# CONTROLSS_EQEP1_CONTROLSS_EQEP1 register map
Vendor: Texas Instruments
Peripheral module from a debugger description file (folder AM263).
Registers are 16-bit, read-write, reset 0x0 unless marked. A register's access mark holds for its fields unless they carry their own. Offsets are as the file gives them; lines under a group give offsets from that group; [hi:lo] are bit positions; {n}, {i} and the like mark numbered series; 'fields as' and 'values as' point back to an identical list; <NAME> marks a mode.

## CONTROLSS_EQEP1_CONTROLSS_EQEP1
0x00 CONTROLSS_EQEP1_QPOSCNT 32-bit
  [31:0] QPOSCNT — Position Counter This 32-bit position counter register counts up/down on every eQEP pulse based on direction input. This counter acts as a position integrator whose count value is proportional to position from a give reference point. This Register acts as a Read ONLY register while counter is counting up/down. Note: It is recommended to only write to the position counter register (QPOSCNT) during initialization, i.e. when the eQEP position counter is disabled (QPEN bit of QEPCTL is zero). Once the position counter is enabled (QPEN bit is one), writing to the eQEP position counter register (QPOSCNT) may cause unexpected results.
0x04 CONTROLSS_EQEP1_QPOSINIT 32-bit
  [31:0] QPOSINIT — Position Counter Init This register contains the position value that is used to initialize the position counter based on external strobe or index event. The position counter can be initialized through software. Writes to this register should always be full 32-bit writes.
0x08 CONTROLSS_EQEP1_QPOSMAX 32-bit
  [31:0] QPOSMAX — Maximum Position Count This register contains the maximum position counter value. Writes to this register should always be full 32-bit writes.
0x0C CONTROLSS_EQEP1_QPOSCMP 32-bit
  [31:0] QPOSCMP — Position Compare The position-compare value in this register is compared with the position counter (QPOSCNT) to generate sync output and/or interrupt on compare match.
0x10 CONTROLSS_EQEP1_QPOSILAT 32-bit ro
  [31:0] QPOSILAT — Index Position Latch The position-counter value is latched into this register on an index event as defined by the QEPCTL[IEL] bits.
0x14 CONTROLSS_EQEP1_QPOSSLAT 32-bit ro
  [31:0] QPOSSLAT — Strobe Position Latch The position-counter value is latched into this register on a strobe event as defined by the QEPCTL[SEL] bits.
0x18 CONTROLSS_EQEP1_QPOSLAT 32-bit ro
  [31:0] QPOSLAT — Position Latch The position-counter value is latched into this register on a unit time out event.
0x1C CONTROLSS_EQEP1_QUTMR 32-bit
  [31:0] QUTMR — QEP Unit Timer This register acts as time base for unit time event generation. When this timer value matches the unit time period value a unit time event is generated.
0x20 CONTROLSS_EQEP1_QUPRD 32-bit
  [31:0] QUPRD — QEP Unit Period This register contains the period count for the unit timer to generate periodic unit time events. These events latch the eQEP position information at periodic intervals and optionally generate an interrupt. Writes to this register should always be full 32-bit writes.
0x24 CONTROLSS_EQEP1_QWDTMR
  [15:0] QWDTMR — QEP Watchdog Timer This register acts as time base for the watchdog to detect motor stalls. When this timer value matches with the watchdog's period value a watchdog timeout interrupt is generated. This register is reset upon edge transition in quadrature-clock indicating the motion.
0x26 CONTROLSS_EQEP1_QWDPRD
  [15:0] QWDPRD — QEP Watchdog Period This register contains the time-out count for the eQEP peripheral watch dog timer. When the watchdog timer value matches the watchdog period value, a watchdog timeout interrupt is generated.
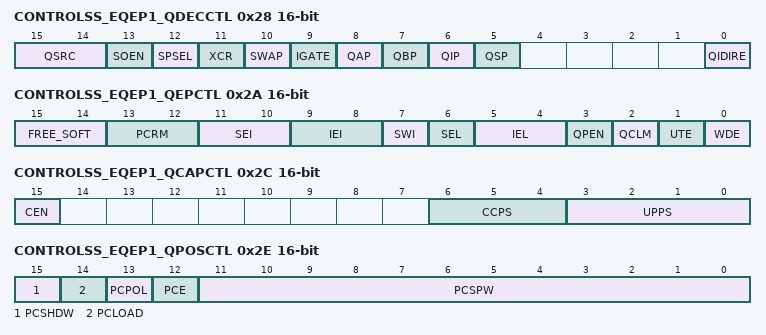
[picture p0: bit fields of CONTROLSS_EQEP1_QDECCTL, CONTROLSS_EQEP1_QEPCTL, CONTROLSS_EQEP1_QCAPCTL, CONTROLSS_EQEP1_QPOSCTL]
0x28 CONTROLSS_EQEP1_QDECCTL
  [15:14] QSRC — Position-counter source selection
  [13] SOEN — Sync output-enable 0 | SYNC_DISABLEDisable position-compare sync output 1 | SYNC_ENABLEEnable position-compare sync output
  [12] SPSEL — Sync output pin selection 0 | INDEX_PINIndex pin is used for sync output 1 | STROBE_PINStrobe pin is used for sync output
  [11] XCR — External Clock Rate 0 | XCR_2XRESOL2x resolution: Count the rising/falling edge 1 | XCR_1XRESOL1x resolution: Count the rising edge only
  [10] SWAP — CLK/DIR Signal Source for Position Counter 0 | SWAP_DISABLEQuadrature-clock inputs are not swapped 1 | SWAP_ENABLEQuadrature-clock inputs are swapped
  [9] IGATE — Index pulse gating option 0 | IGATE_DISABLEDisable gating of Index pulse 1 | IGATE_ENABLEGate the index pin with strobe
  [8] QAP — QEPA input polarity 0 | QAP_NOPOLARNo effect 1 | QAP_POLARNegates QEPA input
  [7] QBP — QEPB input polarity 0 | QBP_NOPOLARNo effect 1 | QBP_POLARNegates QEPB input
  [6] QIP — QEPI input polarity 0 | QIP_NOPOLARNo effect 1 | QIP_POLARNegates QEPI input
  [5] QSP — QEPS input polarity 0 | QSP_NOPOLARNo effect 1 | QSP_POLARNegates QEPS input
  [0] QIDIRE — 0 - Compatible mode, Behavior same as existing devices 1 - Enhancement for Direction change during Index will be enabled
0x2A CONTROLSS_EQEP1_QEPCTL
  [15:14] FREE_SOFT — Emulation mode 0x0 | FREE_SOFT_0QPOSCNT behavior Position counter stops immediately on emulation suspend 0h (R/W) = QWDTMR behavior Watchdog counter stops immediately 0h (R/W) = QUTMR behavior Unit timer stops immediately 0h (R/W) = QCTMR behavior Capture Timer stops immediately 0x1 | FREE_SOFT_1QPOSCNT behavior Position counter continues to count until the rollover 1h (R/W) = QWDTMR behavior Watchdog counter counts until WD period match roll over 1h (R/W) = QUTMR behavior Unit timer counts until period rollover 1h (R/W) = QCTMR behavior Capture Timer counts until next unit period event 0x2 | FREE_SOFT_2QPOSCNT behavior Position counter is unaffected by emulation suspend 2h (R/W) = QWDTMR behavior Watchdog counter is unaffected by emulation suspend 2h (R/W) = QUTMR behavior Unit timer is unaffected by emulation suspend 2h (R/W) = QCTMR behavior Capture Timer is unaffected by emulation suspend 0x3 | FREE_SOFT_3Same as FREE_SOFT_2
  [13:12] PCRM — Postion counter reset 0x0 | PCRM_INDEXPosition counter reset on an index event 0x1 | PCRM_MAXPOSPosition counter reset on the maximum position 0x2 | PCRM_FIRSTINDEXPosition counter reset on the first index event 0x3 | PCRM_TIMEEVENTPosition counter reset on a unit time event
  [11:10] SEI — Strobe event initialization of position counter 0x0 | SEI_NOTHING0Does nothing (action disabled) 0x1 | SEI_NOTHING1Does nothing (action disabled) 0x2 | SEI_INITQEPSRISINGInitializes the position counter on rising edge of the QEPS signal 0x3 | SEI_INITQEPSCLOCKClockwise Direction: Initializes the position counter on the rising edge of QEPS strobe Counter Clockwise Direction: Initializes the position counter on the falling edge of QEPS strobe
  [9:8] IEI — Index event init of position count 0x0 | IEI_NOTHING0Do nothing (action disabled) 0x1 | IEI_NOTHING1Do nothing (action disabled) 0x2 | IEI_INITRISINGInitializes the position counter on the rising edge of the QEPI signal (QPOSCNT = QPOSINIT) 0x3 | IEI_INITFALLINGInitializes the position counter on the falling edge of QEPI signal (QPOSCNT = QPOSINIT)
  [7] SWI — Software init position counter 0 | SWI_NOTHINGDo nothing (action disabled) 1 | SWI_INITPOSInitialize position counter (QPOSCNT=QPOSINIT). This bit is not cleared automatically
  [6] SEL — Strobe event latch of position counter 0 | SEL_QEPSRISINGThe position counter is latched on the rising edge of QEPS strobe (QPOSSLAT = POSCCNT). Latching on the falling edge can be done by inverting the strobe input using the QSP bit in the QDECCTL register 1 | SEL_QEPSCLOCKClockwise Direction: Position counter is latched on rising edge of QEPS strobe Counter Clockwise Direction: Position counter is latched on falling edge of QEPS strobe
  [5:4] IEL — Index event latch of position counter (software index marker) 0x0 | IEL_RSVDReserved 0x1 | IEL_POSRISINGLatches position counter on rising edge of the index signal 0x2 | IEL_POSFALLINGLatches position counter on falling edge of the index signal 0x3 | IEL_SIMSoftware index marker. Latches the position counter and quadrature direction flag on index event marker. The position counter is latched to the QPOSILAT register and the direction flag is latched in the QEPSTS[QDLF] bit. This mode is useful for software index marking.
  [3] QPEN — Quadrature position counter enable/software reset 0 | QPEN_RESETReset the eQEP peripheral internal operating flags/read-only registers. Control/configuration registers are not disturbed by a software reset. When QPEN is disabled, some flags in the QFLG register do not get reset or cleared and show the actual state of that flag. 1 | QPEN_ENABLEeQEP position counter is enabled
  [2] QCLM — QEP capture latch mode 0 | QCLM_CPULatch on position counter read by CPU. Capture timer and capture period values are latched into QCTMRLAT and QCPRDLAT registers when CPU reads the QPOSCNT register. 1 | QCLM_TIMEOUTLatch on unit time out. Position counter, capture timer and capture period values are latched into QPOSLAT, QCTMRLAT and QCPRDLAT registers on unit time out.
  [1] UTE — QEP unit timer enable 0 | UTE_DISABLEDisable eQEP unit timer 1 | UTE_ENABLEEnable unit timer
  [0] WDE — QEP watchdog enable 0 | WDE_DISABLEDisable the eQEP watchdog timer 1 | WDE_ENABLEEnable the eQEP watchdog timer
0x2C CONTROLSS_EQEP1_QCAPCTL
  [15] CEN — Enable eQEP capture 0 | CEN_DISABLEeQEP capture unit is disabled 1 | CEN_ENABLEeQEP capture unit is enabled
  [6:4] CCPS — eQEP capture timer clock prescaler 0x0 | SYSCLKOUT1CAPCLK = SYSCLKOUT/1 0x1 | SYSCLKOUT2CAPCLK = SYSCLKOUT/2 0x2 | SYSCLKOUT4CAPCLK = SYSCLKOUT/4 0x3 | SYSCLKOUT8CAPCLK = SYSCLKOUT/8 0x4 | SYSCLKOUT16CAPCLK = SYSCLKOUT/16 0x5 | SYSCLKOUT32CAPCLK = SYSCLKOUT/32 0x6 | SYSCLKOUT64CAPCLK = SYSCLKOUT/64 0x7 | SYSCLKOUT128CAPCLK = SYSCLKOUT/128
  [3:0] UPPS — Unit position event prescaler 0x0 | QCLK1UPEVNT = QCLK/1 0x1 | QCLK2UPEVNT = QCLK/2 0x2 | QCLK4UPEVNT = QCLK/4 0x3 | QCLK8UPEVNT = QCLK/8 0x4 | QCLK16UPEVNT = QCLK/16 0x5 | QCLK32UPEVNT = QCLK/32 0x6 | QCLK64UPEVNT = QCLK/64 0x7 | QCLK128UPEVNT = QCLK/128 0x8 | QCLK256UPEVNT = QCLK/256 0x9 | QCLK512UPEVNT = QCLK/512 0xA | QCLK1024UPEVNT = QCLK/1024 0xB | QCLK2048UPEVNT = QCLK/2048 0xC | QCLK_RSVD0Reserved 0xD | QCLK_RSVD1Reserved 0xE | QCLK_RSVD2Reserved 0xF | QCLK_RSVD3Reserved
0x2E CONTROLSS_EQEP1_QPOSCTL
  [15] PCSHDW — Position compare of shadow enable 0 | PCSHDW_DISABLEShadow disabled, load Immediate 1 | PCSHDW_ENABLEShadow enabled
  [14] PCLOAD — Position compare of shadow load 0 | PCLOAD_0Load on QPOSCNT = 0 1 | PCLOAD_QPOSCMPLoad when QPOSCNT = QPOSCMP
  [13] PCPOL — Polarity of sync output 0 | PCPOL_HIGHActive HIGH pulse output 1 | PCPOL_LOWActive LOW pulse output
  [12] PCE — Position compare enable/disable 0 | PCE_DISABLEDisable position compare unit 1 | PCE_ENABLEEnable position compare unit
  [11:0] PCSPW — Select-position-compare sync output pulse width 0x000 | SYSCLKOUT41 * 4 * SYSCLKOUT cycles 0x001 | SYSCLKOUT82 * 4 * SYSCLKOUT cycles 0xFFF | SYSCLKOUT163844096 * 4 * SYSCLKOUT cycles
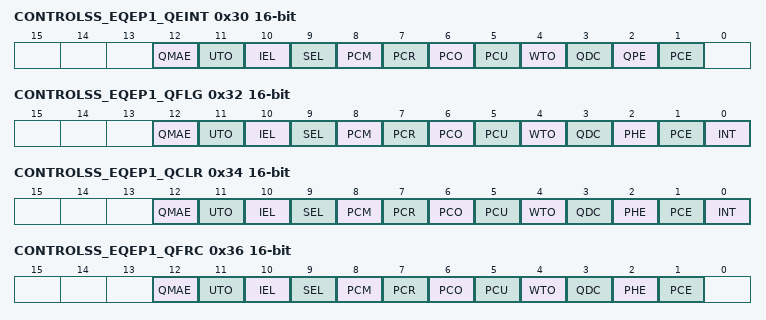
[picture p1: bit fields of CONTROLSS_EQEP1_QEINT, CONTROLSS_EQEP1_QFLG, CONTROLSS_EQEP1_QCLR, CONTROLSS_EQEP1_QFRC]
0x30 CONTROLSS_EQEP1_QEINT
  [12] QMAE — QMA Error Interrupt enable 0 | QMAE_DISABLEInterrupt is disabled 1 | QMAE_ENABLEInterrupt is enabled
  [11] UTO — Unit time out interrupt enable 0 | UTO_DISABLEInterrupt is disabled 1 | UTO_ENABLEInterrupt is enabled
  [10] IEL — Index event latch interrupt enable 0 | IEL_DISABLEInterrupt is disabled 1 | IEL_ENABLEInterrupt is enabled
  [9] SEL — Strobe event latch interrupt enable 0 | SEL_DISABLEInterrupt is disabled 1 | SEL_ENABLEInterrupt is enabled
  [8] PCM — Position-compare match interrupt enable 0 | PCM_DISABLEInterrupt is disabled 1 | PCM_ENABLEInterrupt is enabled
  [7] PCR — Position-compare ready interrupt enable 0 | PCR_DISABLEInterrupt is disabled 1 | PCR_ENABLEInterrupt is enabled
  [6] PCO — Position counter overflow interrupt enable 0 | PCO_DISABLEInterrupt is disabled 1 | PCO_ENABLEInterrupt is enabled
  [5] PCU — Position counter underflow interrupt enable 0 | PCU_DISABLEInterrupt is disabled 1 | PCU_ENABLEInterrupt is enabled
  [4] WTO — Watchdog time out interrupt enable 0 | WTO_DISABLEInterrupt is disabled 1 | WTO_ENABLEInterrupt is enabled
  [3] QDC — Quadrature direction change interrupt enable 0 | QDC_DISABLEInterrupt is disabled 1 | QDC_ENABLEInterrupt is enabled
  [2] QPE — Quadrature phase error interrupt enable 0 | QPE_DISABLEInterrupt is disabled 1 | QPE_ENABLEInterrupt is enabled
  [1] PCE — Position counter error interrupt enable 0 | PCE_DISABLEInterrupt is disabled 1 | PCE_ENABLEInterrupt is enabled
0x32 CONTROLSS_EQEP1_QFLG ro
  [12] QMAE — QMA Error interrupt flag Read0 | QMAE_NOFLAGNo interrupt generated Read1 | QMAE_FLAGInterrupt was generated
  [11] UTO — Unit time out interrupt flag Read0 | UTO_NOFLAGNo interrupt generated Read1 | UTO_FLAGSet by eQEP unit timer period match
  [10] IEL — Index event latch interrupt flag Read0 | IEL_NOFLAGNo interrupt generated Read1 | IEL_FLAGThis bit is set after latching the QPOSCNT to QPOSILAT
  [9] SEL — Strobe event latch interrupt flag Read0 | SEL_NOFLAGNo interrupt generated Read1 | SEL_FLAGThis bit is set after latching the QPOSCNT to QPOSSLAT
  [8] PCM — eQEP compare match event interrupt flag Read0 | PCM_NOFLAGNo interrupt generated Read1 | PCM_FLAGThis bit is set on position-compare match
  [7] PCR — Position-compare ready interrupt flag Read0 | PCR_NOFLAGNo interrupt generated Read1 | PCR_FLAGThis bit is set after transferring the shadow register value to the active position compare register
  [6] PCO — Position counter overflow interrupt flag Read0 | PCO_NOFLAGNo interrupt generated Read1 | PCO_FLAGThis bit is set on position counter overflow.
  [5] PCU — Position counter underflow interrupt flag Read0 | PCU_NOFLAGNo interrupt generated Read1 | PCU_FLAGThis bit is set on position counter underflow.
  [4] WTO — Watchdog timeout interrupt flag Read0 | WTO_NOFLAGNo interrupt generated Read1 | WTO_FLAGSet by watchdog timeout
  [3] QDC — Quadrature direction change interrupt flag Read0 | QDC_NOFLAGNo interrupt generated Read1 | QDC_FLAGInterrupt was generated
  [2] PHE — Quadrature phase error interrupt flag Read0 | PHE_NOFLAGNo interrupt generated Read1 | PHE_FLAGSet on simultaneous transition of QEPA and QEPB
  [1] PCE — Position counter error interrupt flag Read0 | PCE_NOFLAGNo interrupt generated Read1 | PCE_FLAGPosition counter error
  [0] INT — Global interrupt status flag Read0 | INT_NOFLAGNo interrupt generated Read1 | INT_FLAGInterrupt was generated
0x34 CONTROLSS_EQEP1_QCLR access not given
  [12] QMAE — Clear QMA Error interrupt flag 0 | QMAE_NOEFFECTNo effect 1 | QMAE_CLRClears the interrupt flag (access RW RRETURNS0S)
  [11] UTO — Clear unit time out interrupt flag 0 | UTO_NOEFFECTNo effect 1 | UTO_CLRClears the interrupt flag (access RW RRETURNS0S)
  [10] IEL — Clear index event latch interrupt flag 0 | IEL_NOEFFECTNo effect 1 | IEL_CLRClears the interrupt flag (access RW RRETURNS0S)
  [9] SEL — Clear strobe event latch interrupt flag 0 | SEL_NOEFFECTNo effect 1 | SEL_CLRClears the interrupt flag (access RW RRETURNS0S)
  [8] PCM — Clear eQEP compare match event interrupt flag 0 | PCM_NOEFFECTNo effect 1 | PCM_CLRClears the interrupt flag (access RW RRETURNS0S)
  [7] PCR — Clear position-compare ready interrupt flag 0 | PCR_NOEFFECTNo effect 1 | PCR_CLRClears the interrupt flag (access RW RRETURNS0S)
  [6] PCO — Clear position counter overflow interrupt flag 0 | PCO_NOEFFECTNo effect 1 | PCO_CLRClears the interrupt flag (access RW RRETURNS0S)
  [5] PCU — Clear position counter underflow interrupt flag 0 | PCU_NOEFFECTNo effect 1 | PCU_CLRClears the interrupt flag (access RW RRETURNS0S)
  [4] WTO — Clear watchdog timeout interrupt flag 0 | WTO_NOEFFECTNo effect 1 | WTO_CLRClears the interrupt flag (access RW RRETURNS0S)
  [3] QDC — Clear quadrature direction change interrupt flag 0 | QDC_NOEFFECTNo effect 1 | QDC_CLRClears the interrupt flag (access RW RRETURNS0S)
  [2] PHE — Clear quadrature phase error interrupt flag 0 | PHE_NOEFFECTNo effect 1 | PHE_CLRClears the interrupt flag (access RW RRETURNS0S)
  [1] PCE — Clear position counter error interrupt flag 0 | PCE_NOEFFECTNo effect 1 | PCE_CLRClears the interrupt flag (access RW RRETURNS0S)
  [0] INT — Global interrupt clear flag 0 | INT_NOEFFECTNo effect 1 | INT_CLRClears the interrupt flag (access RW RRETURNS0S)
0x36 CONTROLSS_EQEP1_QFRC
  [12] QMAE — Force QMA error interrupt 0 | QMAE_NOEFFECTNo effect 1 | QMAE_FORCEForce the interrupt
  [11] UTO — Force unit time out interrupt 0 | UTO_NOEFFECTNo effect 1 | UTO_FORCEForce the interrupt
  [10] IEL — Force index event latch interrupt 0 | IEL_NOEFFECTNo effect 1 | IEL_FORCEForce the interrupt
  [9] SEL — Force strobe event latch interrupt 0 | SEL_NOEFFECTNo effect 1 | SEL_FORCEForce the interrupt
  [8] PCM — Force position-compare match interrupt 0 | PCM_NOEFFECTNo effect 1 | PCM_FORCEForce the interrupt
  [7] PCR — Force position-compare ready interrupt 0 | PCR_NOEFFECTNo effect 1 | PCR_FORCEForce the interrupt
  [6] PCO — Force position counter overflow interrupt 0 | PCO_NOEFFECTNo effect 1 | PCO_FORCEForce the interrupt
  [5] PCU — Force position counter underflow interrupt 0 | PCU_NOEFFECTNo effect 1 | PCU_FORCEForce the interrupt
  [4] WTO — Force watchdog time out interrupt 0 | WTO_NOEFFECTNo effect 1 | WTO_FORCEForce the interrupt
  [3] QDC — Force quadrature direction change interrupt 0 | QDC_NOEFFECTNo effect 1 | QDC_FORCEForce the interrupt
  [2] PHE — Force quadrature phase error interrupt 0 | PHE_NOEFFECTNo effect 1 | PHE_FORCEForce the interrupt
  [1] PCE — Force position counter error interrupt 0 | PCE_NOEFFECTNo effect 1 | PCE_FORCEForce the interrupt
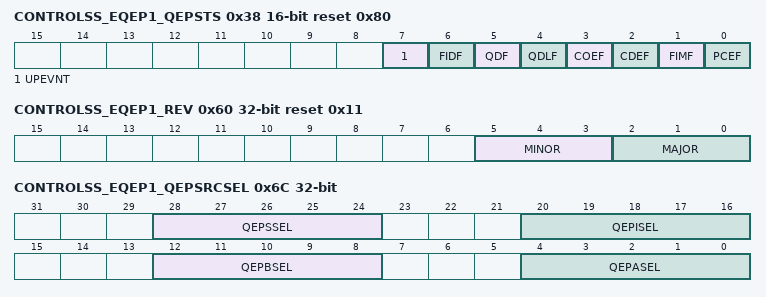
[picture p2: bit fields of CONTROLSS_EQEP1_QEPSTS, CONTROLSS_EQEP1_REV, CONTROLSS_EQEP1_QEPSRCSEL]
0x38 CONTROLSS_EQEP1_QEPSTS access per field reset 0x80
  [7] UPEVNT rw — Unit position event flag 0 | UPEVNT_NODETCTNo unit position event detected 1 | UPEVNT_DETCTUnit position event detected. Write 1 to clear
  [6] FIDF ro — Direction on the first index marker Status of the direction is latched on the first index event marker. Read0 | FIDF_COUNTERCLKCounter-clockwise rotation (or reverse movement) on the first index event Read1 | FIDF_CLKClockwise rotation (or forward movement) on the first index event
  [5] QDF ro — Quadrature direction flag Read0 | QDF_COUNTERCLKCounter-clockwise rotation (or reverse movement) Read1 | QDF_CLKClockwise rotation (or forward movement)
  [4] QDLF ro — eQEP direction latch flag Read0 | QDLF_COUNTERCLKCounter-clockwise rotation (or reverse movement) on index event marker Read1 | QDLF_CLKClockwise rotation (or forward movement) on index event marker
  [3] COEF rw — Capture overflow error flag 0 | COEF_WRT1Overflow has not occurred. 1 | COEF_OVFOverflow occurred in eQEP Capture timer (QEPCTMR). This bit is cleared by writing a '1'.
  [2] CDEF rw — Capture direction error flag 0 | CDEF_WRT1Capture direction error has not occurred. 1 | CDEF_DIRECTDirection change occurred between the capture position event. This bit is cleared by writing a '1'.
  [1] FIMF rw — First index marker flag 0 | FIMF_WRT1First index pulse has not occurred. 1 | FIMF_SETINDEXSet by first occurrence of index pulse. This bit is cleared by writing a '1'.
  [0] PCEF ro — Position counter error flag. This bit is not sticky and it is updated for every index event. Read0 | PCEF_NOERRORNo error occurred during the last index transition Read1 | PCEF_ERRORPosition counter error
0x3A CONTROLSS_EQEP1_QCTMR
  [15:0] QCTMR — This register provides time base for edge capture unit.
0x3C CONTROLSS_EQEP1_QCPRD
  [15:0] QCPRD — This register holds the period count value between the last successive eQEP position events
0x3E CONTROLSS_EQEP1_QCTMRLAT ro
  [15:0] QCTMRLAT — The eQEP capture timer value can be latched into this register on two events viz., unit timeout event, reading the eQEP position counter.
0x40 CONTROLSS_EQEP1_QCPRDLAT ro
  [15:0] QCPRDLAT — eQEP capture period value can be latched into this register on two events viz., unit timeout event, reading the eQEP position counter.
0x60 CONTROLSS_EQEP1_REV 32-bit ro reset 0x11
  [5:3] MINOR — This field specifies the Minor Revision number for the eQEP IP.
  [2:0] MAJOR — This field specifies the Major Revision number for the eQEP IP.
0x64 CONTROLSS_EQEP1_QEPSTROBESEL 32-bit
  [1:0] STROBESEL — Strobe source select: 0x0 | QS_AFTER_POL_MUXQEP Strobe after polarity mux 0x1 | QS_AFTER_POL_MUXQEP Strobe after polarity mux 0x2 | ADCSOCA_AS_QSQEP Strobe after polarity mux ORed with ADCSOCA 0x3 | ADCSOCB_AS_QSQEP Strobe after polarity mux ORed with ADCSOCB
0x68 CONTROLSS_EQEP1_QMACTRL 32-bit
  [2:0] MODE — Select Mode for QMA mode: 000 : QMA Module is bypassed. 001 : QMA Mode-1 operation selected 010 : QMA Mode-2 operation selected 011 : QMA Module is bypassed (reserved) 1xx : QMA Module is bypassed (reserved)
0x6C CONTROLSS_EQEP1_QEPSRCSEL 32-bit
  [28:24] QEPSSEL — QEP Strobe source select: 0x0: Device Pin (Default) 0x1 to 0x1F : To be defined in SOC context Note: eQEP needs to be disabled before configuring these bits as it can lead to unexpected behavior if eQEP is running.
  [20:16] QEPISEL — QEP Index source select: 0x0: Device Pin (Default) 0x1 to 0x1F : To be defined in SOC context Note: eQEP needs to be disabled before configuring these bits as it can lead to unexpected behavior if eQEP is running.
  [12:8] QEPBSEL — QEPB source select: 0x0: Device Pin (Default) 0x1 to 0x1F : To be defined in SOC context Note: eQEP needs to be disabled before configuring these bits as it can lead to unexpected behavior if eQEP is running.
  [4:0] QEPASEL — QEPA source select: 0x0: Device Pin (Default) 0x1 to 0x1F : To be defined in SOC context Note: eQEP needs to be disabled before configuring these bits as it can lead to unexpected behavior if eQEP is running.
